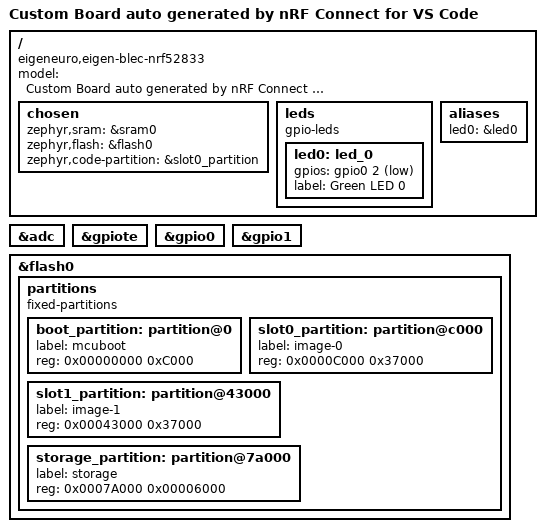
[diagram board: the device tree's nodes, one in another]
/dts-v1/;
#include <nordic/nrf52833_qdaa.dtsi>
#include "eigen_blec_nrf52833-pinctrl.dtsi"

/ {
	model = "Custom Board auto generated by nRF Connect for VS Code";
	compatible = "eigeneuro,eigen-blec-nrf52833";

	chosen {
		zephyr,sram = &sram0;
		zephyr,flash = &flash0;
		zephyr,code-partition = &slot0_partition;
	};

	leds {
		compatible = "gpio-leds";

		led0: led_0 {
			gpios = <&gpio0 2 GPIO_ACTIVE_LOW>;
			label = "Green LED 0";
		};
  };

  aliases {
      led0 = &led0;
  };
};

&adc {
	status = "okay";
};

&gpiote {
	status = "okay";
};

&gpio0 {
	status = "okay";
};

&gpio1 {
	status = "okay";
};

&flash0 {
  status = "okay";

	partitions {
		compatible = "fixed-partitions";
		#address-cells = <1>;
		#size-cells = <1>;

		boot_partition: partition@0 {
			label = "mcuboot";
			reg = <0x00000000 0xC000>;
		};

		slot0_partition: partition@c000 {
			label = "image-0";
			reg = <0x0000C000 0x37000>;
		};

		slot1_partition: partition@43000 {
			label = "image-1";
			reg = <0x00043000 0x37000>;
		};

		storage_partition: partition@7a000 {
			label = "storage";
			reg = <0x0007A000 0x00006000>;
		};
	};
};
